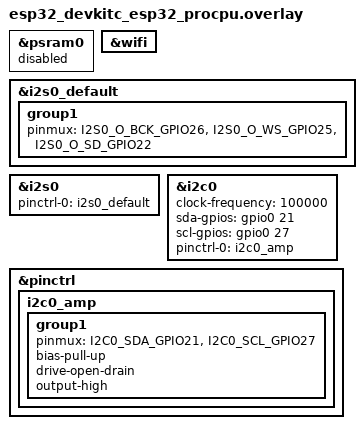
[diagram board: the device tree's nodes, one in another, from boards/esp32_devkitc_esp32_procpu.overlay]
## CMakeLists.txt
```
cmake_minimum_required(VERSION 3.20.0)
list(APPEND ZEPHYR_EXTRA_MODULES ${CMAKE_CURRENT_LIST_DIR}/../..)
find_package(Zephyr REQUIRED HINTS $ENV{ZEPHYR_BASE})
project(eaf_esp32_sendspin)
# Keep the optional silent backend within the WROOM budget; match all TUs.
zephyr_compile_definitions(EAF_NULL_MAX_FRAMES=128u)
set(EAF_PRIVATE_CONFIG "${CMAKE_CURRENT_SOURCE_DIR}/credentials.local.h" CACHE FILEPATH "Local Wi-Fi credentials header")
if(EXISTS "${EAF_PRIVATE_CONFIG}")
  configure_file("${EAF_PRIVATE_CONFIG}" private/credentials.h COPYONLY)
else()
  configure_file(credentials.example.h private/credentials.h COPYONLY)
  message(STATUS "No local Wi-Fi credentials: image builds but will not connect")
endif()
target_include_directories(app PRIVATE ${CMAKE_CURRENT_BINARY_DIR}/private)
target_sources(app PRIVATE src/main.c)
target_sources(app PRIVATE ${CMAKE_CURRENT_SOURCE_DIR}/../esp32_output/board_output.c)
target_sources(app PRIVATE ${CMAKE_CURRENT_SOURCE_DIR}/../esp32_common/log_buffer.c
  ${CMAKE_CURRENT_SOURCE_DIR}/../esp32_common/diagnostics.c
  ${CMAKE_CURRENT_SOURCE_DIR}/../esp32_common/tas5805m.c
  ${CMAKE_CURRENT_SOURCE_DIR}/../esp32_common/tas5805m_zephyr.c
  ${CMAKE_CURRENT_SOURCE_DIR}/../esp32_common/wifi_bootstrap.c
  ${CMAKE_CURRENT_SOURCE_DIR}/../esp32_common/board_runtime.c)
target_include_directories(app PRIVATE ${CMAKE_CURRENT_SOURCE_DIR}/../esp32_output
  ${CMAKE_CURRENT_SOURCE_DIR}/../esp32_common
  ${CMAKE_CURRENT_SOURCE_DIR}/../../hal/zephyr)
if(CONFIG_EAF_BOARD_I2S)
  target_sources(app PRIVATE ${CMAKE_CURRENT_SOURCE_DIR}/../esp32_output/sink_i2s.c)
else()
  target_sources(app PRIVATE ${CMAKE_CURRENT_SOURCE_DIR}/../esp32_output/sink_null.c)
endif()
if(CONFIG_EAF_BOARD_USE_PSRAM)
  target_sources(app PRIVATE ${CMAKE_CURRENT_SOURCE_DIR}/../esp32_output/storage_psram.c)
else()
  target_sources(app PRIVATE ${CMAKE_CURRENT_SOURCE_DIR}/../esp32_output/storage_internal.c)
endif()
if(CONFIG_WIFI_ESP32)
  target_sources(app PRIVATE ${CMAKE_CURRENT_SOURCE_DIR}/../esp32_common/wifi_power_esp32.c)
else()
  target_sources(app PRIVATE ${CMAKE_CURRENT_SOURCE_DIR}/../esp32_common/wifi_power_stub.c)
endif()
if(CONFIG_BOOTLOADER_MCUBOOT)
  target_sources(app PRIVATE ${CMAKE_CURRENT_SOURCE_DIR}/../esp32_common/ota_mcuboot.c)
else()
  target_sources(app PRIVATE ${CMAKE_CURRENT_SOURCE_DIR}/../esp32_common/ota_stub.c)
endif()

target_include_directories(app SYSTEM PRIVATE ${ZEPHYR_BASE}/include)
target_compile_options(app PRIVATE -Wall -Wextra -Werror -Wconversion -Wstrict-prototypes -Wshadow -Wdouble-promotion)
```

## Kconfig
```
mainmenu "EAF WROOM Sendspin player"
config EAF_I2S_MAX_FRAMES
    default 128
source "Kconfig.zephyr"
config EAF_BOARD_I2S
    bool "Audible I2S output (otherwise timed null)"
    default y
    select I2S
    select EAF_I2S
config EAF_BOARD_NAME
    string "Player name advertised to the server"
    default "EAF Sendspin"
    help
      Human-readable name shown in Music Assistant. Set a distinct value per
      board so multiple players are easy to tell apart.

config EAF_BOARD_CLIENT_ID
    string "Sendspin client identifier"
    default "eaf-sendspin"
    help
      Stable identifier for this player. Changing it makes the server treat
      the board as a new player.

config EAF_BOARD_SERVER
    string "Sendspin server numeric IPv4 address"
    default ""
    help
      Music Assistant host IPv4 address. Required; the board logs an error and
      stops when it is empty. Provide it locally, for example with a local
      override file passed as -DEXTRA_CONF_FILE=local.conf containing
      CONFIG_EAF_BOARD_SERVER="192.168.1.10".
config EAF_BOARD_PORT
    int "Sendspin server port"
    default 8927
    range 1 65535
config EAF_SOURCE_CHANNELS
    int "Source PCM channels advertised to the server"
    default 2
    range 1 2
    help
      Ask Music Assistant to send this many channels. The board still outputs
      stereo (the producer duplicates one channel when mono), but the network
      rate drops when set to 1, which is more reliable on throughput-limited
      2.4 GHz Wi-Fi.

choice EAF_BIT_DEPTH_CHOICE
    prompt "Source PCM bit depth advertised to the server"
    default EAF_BIT_DEPTH_16
    help
      Precision of the PCM the server sends. The board always presents 32-bit
      Q1.31 to the I2S sink; the network rate grows with the chosen precision.

config EAF_BIT_DEPTH_16
    bool "16-bit"
config EAF_BIT_DEPTH_24
    bool "24-bit"
config EAF_BIT_DEPTH_32
    bool "32-bit"
endchoice

config EAF_BIT_DEPTH
    int
    default 16 if EAF_BIT_DEPTH_16
    default 24 if EAF_BIT_DEPTH_24
    default 32 if EAF_BIT_DEPTH_32

config EAF_SAMPLE_RATE
    int "Source sample rate advertised to the server"
    default 44100
    range 8000 192000
    help
      Music Assistant transcodes to this rate. Lowering it (for example 22050)
      further reduces the network rate when even mono 44.1 kHz is marginal.

config EAF_AMP_PWDN_GPIO
    int "TAS5805M PDN GPIO (amplifier enable)"
    default 33
    range 0 39
config EAF_AMP_FAULT_GPIO
    int "TAS5805M FAULT GPIO (input)"
    default 34
    range 0 39
config EAF_BOARD_RATE_CONTROL
    bool "Hold presentation latency with drift resampling"
    default y
    help
      Resample the PCM written to the sink to hold the measured Sendspin
      presentation latency at the reported lead time. Required for synchronized
      multiroom playback; the correction is bounded to a few hundred ppm.

config EAF_BOARD_WIFI_PS_NONE
    bool "Disable Wi-Fi modem sleep for lower latency"
    default y
    help
      ESP-IDF defaults to WIFI_PS_MIN_MODEM, which wakes only at the AP DTIM
      period. On a mains-powered player, disabling power save removes those
      periodic receive stalls at the cost of higher idle current.
config EAF_BOARD_AUDIO_CPU
    int "Audio worker CPU (-1 unrestricted)"
    default -1
    help
      With CONFIG_SMP and CONFIG_SCHED_CPU_MASK, pin the audio owner to this
      CPU so network work cannot preempt it. -1 leaves it unrestricted.
config EAF_BOARD_MAIN_CPU
    int "Main/transport CPU (-1 unrestricted)"
    default -1
config EAF_BOARD_RESERVOIR_FRAMES
    int "Output reservoir capacity in frames (power of two)"
    default 4096
    range 512 1048576
    help
      Stereo Q1.31 output reservoir capacity. Also caps the startup prefill.
      Must be a power of two.
config EAF_BOARD_USE_PSRAM
    bool "Place the output reservoir in external SPI RAM"
    default n
    depends on ESP_SPIRAM
    help
      Allocate the reservoir from the ESP32 external RAM shared heap. Enables
      the large-buffer WROVER profile; requires CONFIG_ESP_SPIRAM and PSRAM.
```

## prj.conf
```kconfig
CONFIG_EAF=y
CONFIG_EAF_SENDPIN=y
CONFIG_EAF_LMS=n
CONFIG_EAF_LMS_CLIENT=n
CONFIG_EAF_BT_INGRESS=n
CONFIG_EAF_BT_SBC=n
CONFIG_EAF_BT_A2DP=n
CONFIG_EAF_THREAD_COUNT=1
CONFIG_EAF_THREAD_STACK_SIZE=4096
CONFIG_MAIN_STACK_SIZE=6144
CONFIG_MAIN_THREAD_PRIORITY=5
CONFIG_EAF_SEM_COUNT=1
CONFIG_ASSERT=y
CONFIG_REBOOT=y
CONFIG_THREAD_STACK_INFO=y
CONFIG_INIT_STACKS=y
CONFIG_REQUIRES_FULL_LIBC=y
CONFIG_WIFI=y
CONFIG_NET_L2_WIFI_MGMT=y
CONFIG_NETWORKING=y
CONFIG_I2C=y
CONFIG_NET_IPV4=y
CONFIG_NET_IPV6=n
CONFIG_NET_TCP=y
CONFIG_NET_DHCPV4=y
CONFIG_NET_SOCKETS=y
CONFIG_NET_MGMT=y
CONFIG_NET_MGMT_EVENT=y
CONFIG_NET_MGMT_EVENT_INFO=y
CONFIG_NET_MAX_CONTEXTS=10
CONFIG_NET_MAX_CONN=12
CONFIG_NET_PKT_RX_COUNT=12
CONFIG_NET_PKT_TX_COUNT=8
CONFIG_NET_BUF_RX_COUNT=64
CONFIG_NET_BUF_TX_COUNT=16
CONFIG_NET_BUF_DATA_SIZE=256
CONFIG_NET_TCP_MAX_RECV_WINDOW_SIZE=8192
CONFIG_NET_CONTEXT_RCVTIMEO=y
CONFIG_NET_CONTEXT_SNDTIMEO=y
CONFIG_HEAP_MEM_POOL_SIZE=65536
```

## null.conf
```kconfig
CONFIG_EAF_BOARD_I2S=n
```

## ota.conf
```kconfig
# MCUboot OTA profile (ESP32).
#
# Requires a one-time flash of the MCUboot bootloader and this application to
# slot0; afterwards the running app can write slot1 over HTTP and request an
# upgrade. Enable with:
#   -DEXTRA_CONF_FILE="psram.conf;ota.conf"
CONFIG_ESP_SIMPLE_BOOT=n
CONFIG_BOOTLOADER_MCUBOOT=y
CONFIG_IMG_MANAGER=y
CONFIG_MCUBOOT_IMG_MANAGER=y
CONFIG_FLASH=y
CONFIG_FLASH_MAP=y
CONFIG_FLASH_PAGE_LAYOUT=y
CONFIG_STREAM_FLASH=y
CONFIG_MPU_ALLOW_FLASH_WRITE=y
CONFIG_REBOOT=y
```

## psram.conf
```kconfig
# WROVER-IE / ESP32-WROVER-E (N16R8 or similar) profile.
#
# Enable the 8 MB SPI RAM and place the stereo Q1.31 output reservoir there.
# 65536 frames (~1.5 s of 44.1 kHz stereo source) gives the jitter buffer needed
# to ride out Wi-Fi throughput dips that starve the 4096-frame WROOM profile.
#
# Build with:
#   cmake ... -DEXTRA_CONF_FILE=psram.conf -DEXTRA_DTC_OVERLAY_FILE=psram.overlay

# ESP32-WROVER-E N16R8: 16 MB flash (overrides the WROOM board's 4 MB).
CONFIG_ESPTOOLPY_FLASHSIZE_16MB=y

CONFIG_ESP_SPIRAM=y
CONFIG_ESP_SPIRAM_MEMTEST=y
CONFIG_ESP_SPIRAM_HEAP_SIZE=2097152
# The 2 MB SPIRAM heap exceeds the small-heap limit (262136 B), which is the
# 32-bit default when SRAM_SIZE <= 256. Use the runtime-sized heap.
CONFIG_SYS_HEAP_AUTO=y

CONFIG_EAF_BOARD_USE_PSRAM=y
CONFIG_EAF_BOARD_RESERVOIR_FRAMES=65536

# The larger PSRAM jitter buffer targets stereo; override the WROOM mono default.
CONFIG_EAF_SOURCE_CHANNELS=2
```

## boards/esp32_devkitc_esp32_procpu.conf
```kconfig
# WROOM has no external RAM. The upstream DevKitC template names a WROVER.
CONFIG_ESP_SPIRAM=n
CONFIG_ESP_SIMPLE_BOOT=y
CONFIG_ESPTOOLPY_FLASHSIZE_4MB=y
CONFIG_ESPTOOLPY_FLASHMODE_DIO=y
CONFIG_ESPTOOLPY_FLASHFREQ_40M=y
CONFIG_ESP32_WIFI_STATIC_RX_BUFFER_NUM=10
CONFIG_ESP32_WIFI_DYNAMIC_RX_BUFFER_NUM=16
CONFIG_ESP32_WIFI_DYNAMIC_TX_BUFFER_NUM=8
# AMPDU block-ack window; default 6 is low for a crowded 2.4 GHz link.
CONFIG_ESP32_WIFI_RX_BA_WIN=10

# The application owns DHCP and retry timing.
CONFIG_ESP32_WIFI_STA_AUTO_DHCPV4=n
CONFIG_ESP32_WIFI_STA_RECONNECT=n

# Back the TCP receive window with enough RX buffers for real-time PCM intake.
CONFIG_NET_TCP_MAX_RECV_WINDOW_SIZE=16384
CONFIG_NET_BUF_RX_COUNT=96
CONFIG_NET_PKT_RX_COUNT=24

# WROOM Wi-Fi cannot reliably sustain 176 kB/s stereo PCM16. Ask MA for mono
# (~88 kB/s); the producer still expands it to stereo for the I2S sink. The
# WROVER/PSRAM profile overrides this back to stereo.
CONFIG_EAF_SOURCE_CHANNELS=1

# Zephyr 4.3's ESP32 Wi-Fi driver depends on !SMP, so dual-core pinning is not
# available with networking. Keep audio above network work on the single core:
# the TCP worker default (2) outranks EAF audio (3); move it below.
CONFIG_NET_TCP_WORKER_PRIO=5
```

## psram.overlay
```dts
&psram0 { status = "okay"; };
```

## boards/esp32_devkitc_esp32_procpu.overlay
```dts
#include <zephyr/dt-bindings/gpio/gpio.h>
#include <zephyr/dt-bindings/pinctrl/esp-pinctrl-common.h>
#include <zephyr/dt-bindings/pinctrl/esp32-gpio-sigmap.h>
#include <zephyr/dt-bindings/pinctrl/esp32-pinctrl.h>

&psram0 { status = "disabled"; };
&wifi { status = "okay"; };

/* Board 2 (WROVER + TAS5805M): I2S WS=25, BCLK=26, DIN=22. */
&i2s0_default {
    group1 {
        pinmux = <I2S0_O_BCK_GPIO26>, <I2S0_O_WS_GPIO25>, <I2S0_O_SD_GPIO22>;
    };
};
&i2s0 {
    status = "okay";
    pinctrl-0 = <&i2s0_default>;
    pinctrl-names = "default";
};

/* TAS5805M I2C: SDA=GPIO21, SCL=GPIO27. */
&i2c0 {
    status = "okay";
    clock-frequency = <100000>;
    sda-gpios = <&gpio0 21 GPIO_OPEN_DRAIN>;
    scl-gpios = <&gpio0 27 GPIO_OPEN_DRAIN>;
    pinctrl-0 = <&i2c0_amp>;
    pinctrl-names = "default";
};
&pinctrl {
    i2c0_amp: i2c0_amp {
        group1 {
            pinmux = <I2C0_SDA_GPIO21>, <I2C0_SCL_GPIO27>;
            bias-pull-up;
            drive-open-drain;
            output-high;
        };
    };
};
```

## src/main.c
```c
#include "board_runtime.h"
#include "diagnostics.h"
#include "ota.h"
#include "tas5805m.h"
#include "wifi_bootstrap.h"
#include <board_output.h>
#include <eaf/eaf_hal.h>
#include <eaf/eaf_sendspin_client.h>
#include <eaf/eaf_sendspin_player.h>
#include <string.h>
#include <zephyr/kernel.h>
#include <zephyr/net/net_if.h>
#include <zephyr/sys/reboot.h>

/* dhcpv4.h requires the net_if declaration first. */
#include <zephyr/net/dhcpv4.h>
#include <zephyr/net/net_mgmt.h>
#include <zephyr/net/wifi_mgmt.h>
#include <zephyr/sys/byteorder.h>

BUILD_ASSERT(!IS_ENABLED(CONFIG_BT), "Qualify Wi-Fi alone before enabling Bluetooth");

static eaf_sendspin_client_t client;
static eaf_sendspin_player_t player;
static const tas5805m_io_t *board_amp;
static board_wifi_t wifi;
static atomic_t chunks;

static void sendspin_output_log(const char *message) {
    board_log("%s", message);
}

static uint32_t board_write(void *ctx, const int32_t *samples, uint32_t frames) {
    (void)ctx;
    return eaf_board_output_write(samples, frames);
}
static void on_ready(void *ctx, const eaf_sendspin_server_hello_t *hello) {
    (void)ctx;
    board_log("Sendspin ready: %.*s player=%d\n", (int)hello->name_length, hello->name,
              (int)hello->player_active);
}
static eaf_sendspin_stream_start_t current_stream;
static bool have_stream;

static void apply_volume(void);

static void start_output(const eaf_sendspin_stream_start_t *start) {
    have_stream = false;
    eaf_sendspin_player_finish(&player);
    eaf_format_t format = {.sample_rate = start->sample_rate,
                           .num_channels = 2,
                           .channel_mask = EAF_CH_FRONT_LEFT | EAF_CH_FRONT_RIGHT};
    uint32_t capacity = eaf_board_output_capacity_frames();
    int rc = eaf_board_output_replace(&format, capacity * 3u / 4u, false);
    if (!rc)
        rc = eaf_sendspin_player_begin(&player, &client.filter, start);
    if (rc) {
        board_log("Stream start failed rc=%d\n", rc);
    } else {
        have_stream = true;
        apply_volume();
        if (board_amp)
            (void)tas5805m_play(board_amp);
        board_log("Stream: %u Hz %u-bit %u ch\n", start->sample_rate, start->bit_depth,
                  start->channels);
    }
}
static void on_stream_start(void *ctx, const eaf_sendspin_stream_start_t *start) {
    (void)ctx;
    current_stream = *start;
    start_output(start);
}
static void on_audio(void *ctx, const eaf_sendspin_stream_start_t *format, int64_t timestamp_us,
                     const uint8_t *pcm, size_t length) {
    (void)ctx;
    (void)format;
    uint32_t before = player.frames_written;
    (void)eaf_sendspin_player_write(&player, timestamp_us, pcm, length);
    if (player.frames_written != before)
        atomic_inc(&chunks);
}
static void on_stream_end(void *ctx, bool end_player) {
    (void)ctx;
    if (end_player) {
        have_stream = false;
        eaf_sendspin_player_finish(&player);
        eaf_board_output_finish();
    }
}
static void on_stream_clear(void *ctx, bool clear_player) {
    (void)ctx;
    if (clear_player && have_stream) {
        board_log("Stream clear; flushing buffered audio\n");
        start_output(&current_stream);
    }
}
static int32_t volume_level = 100;
static bool volume_muted;

/* Perceptual square-law mapping from the server's 0..100 to Q1.31 gain. */
static int32_t volume_to_gain(int32_t percent) {
    if (percent <= 0)
        return 0;
    if (percent >= 100)
        return INT32_MAX;
    int64_t value = percent;
    return (int32_t)(value * value * INT32_MAX / 10000);
}
static void apply_volume(void) {
    int32_t gain = volume_muted ? 0 : volume_to_gain(volume_level);
    (void)eaf_board_output_volume(gain, gain);
}
static void on_command(void *ctx, const eaf_sendspin_server_command_t *command) {
    (void)ctx;
    if (command->command == EAF_SENDPIN_COMMAND_VOLUME && command->volume >= 0) {
        volume_level = command->volume;
        board_log("Volume=%d\n", volume_level);
        apply_volume();
    } else if (command->command == EAF_SENDPIN_COMMAND_MUTE) {
        volume_muted = command->muted;
        board_log("Mute=%d\n", (int)volume_muted);
        apply_volume();
    }
}
static void on_disconnect(void *ctx) {
    (void)ctx;
    board_log("Sendspin disconnected\n");
}

int main(void) {
    board_diagnostics_start();
    if (board_wifi_bind(&wifi) != EAF_OK)
        return 1;
    struct in_addr server;
    if (!strlen(CONFIG_EAF_BOARD_SERVER) ||
        net_addr_pton(AF_INET, CONFIG_EAF_BOARD_SERVER, &server)) {
        board_log("Set CONFIG_EAF_BOARD_SERVER to the Music Assistant IPv4 address\n");
        return 1;
    }

    int32_t *storage;
    uint32_t frames;
    if (eaf_board_output_storage(&storage, &frames)) {
        board_log("Output storage allocation failed\n");
        return 1;
    }
    eaf_board_output_config_t output_config = {.audio_cpu = CONFIG_EAF_BOARD_AUDIO_CPU,
                                               .log = sendspin_output_log,
                                               .storage = storage,
                                               .capacity_frames = frames};
    if (eaf_board_output_init(&output_config)) {
        board_log("Output initialization failed\n");
        return 1;
    }
    board_amp = tas5805m_board_io();
    (void)tas5805m_bringup(board_amp);
    eaf_sendspin_player_init(&player, board_write, NULL);

    uint32_t capacity = eaf_board_output_capacity_frames();
    uint32_t capacity_ms = capacity * 1000u / CONFIG_EAF_SAMPLE_RATE;
    if (IS_ENABLED(CONFIG_EAF_BOARD_RATE_CONTROL))
        eaf_sendspin_player_set_rate_control(&player, 0.0); /* auto target */
    eaf_sendspin_config_t config = {.client_id = CONFIG_EAF_BOARD_CLIENT_ID,
                                    .name = CONFIG_EAF_BOARD_NAME,
                                    .product_name = CONFIG_EAF_BOARD_NAME,
                                    .manufacturer = "EAF",
                                    .software_version = "phase2",
                                    .sample_rate = CONFIG_EAF_SAMPLE_RATE,
                                    .bit_depth = CONFIG_EAF_BIT_DEPTH,
                                    .support_volume = true,
                                    .support_mute = true,
                                    .volume = 100,
                                    .static_delay_ms = 0,
                                    .required_lead_time_ms = (int32_t)capacity_ms,
                                    .min_buffer_ms = (int32_t)capacity_ms};
    config.channels = CONFIG_EAF_SOURCE_CHANNELS;
    config.buffer_capacity =
        capacity * CONFIG_EAF_SOURCE_CHANNELS * (uint32_t)(CONFIG_EAF_BIT_DEPTH / 8);
    eaf_sendspin_callbacks_t callbacks = {.ready = on_ready,
                                          .stream_start = on_stream_start,
                                          .audio = on_audio,
                                          .stream_end = on_stream_end,
                                          .stream_clear = on_stream_clear,
                                          .command = on_command,
                                          .disconnected = on_disconnect};
    eaf_sendspin_client_init(&client, &config, &callbacks, NULL);

    board_log("EAF Sendspin board: server %s:%d\n", CONFIG_EAF_BOARD_SERVER, CONFIG_EAF_BOARD_PORT);
    for (;;) {
        int rc = board_wifi_online(&wifi) ? EAF_OK : board_wifi_connect(&wifi);
        if (!rc)
            rc = eaf_sendspin_client_connect(&client, sys_be32_to_cpu(server.s_addr),
                                             (uint16_t)CONFIG_EAF_BOARD_PORT, 3000);
        if (rc) {
            board_log("Sendspin connect failed rc=%d\n", rc);
            k_sleep(K_SECONDS(3));
            continue;
        }
        board_log("Sendspin connected; select this player in Music Assistant\n");
        int64_t report = 0;
        uint64_t previous_rx = client.rx_total;
        int64_t previous_ms = k_uptime_get();
        while (!rc && board_wifi_online(&wifi) && !eaf_board_output_failed()) {
            /* Drain the socket greedily so the server's TCP window stays open. */
            uint64_t before = client.rx_total;
            for (unsigned i = 0; i < 8 && !rc; ++i) {
                rc = eaf_sendspin_client_step(&client);
                if (client.rx_total == before)
                    break;
                before = client.rx_total;
            }
            int64_t now = k_uptime_get();
            if (now >= report) {
                uint64_t span = (uint64_t)(now - previous_ms);
                uint64_t rate = span ? (client.rx_total - previous_rx) * 1000u / span : 0;
                board_log("Sendspin chunks=%u written=%u dropped=%u underruns=%u sync=%d "
                          "lat_ms=%lld level=%u flags=%u rx=%llu B/s vol=%d mute=%d ppm=%d "
                          "fault=%d\n",
                          (unsigned)atomic_get(&chunks), player.frames_written,
                          player.frames_dropped, eaf_board_output_underruns(),
                          (int)player.synchronized, (long long)(player.last_latency_us / 1000),
                          eaf_board_output_level(), eaf_board_output_flags(),
                          (unsigned long long)rate, volume_level, (int)volume_muted,
                          (int)player.rate_ppm, board_amp ? (int)tas5805m_fault(board_amp) : 0);
                board_wifi_health(&wifi);
                previous_rx = client.rx_total;
                previous_ms = now;
                report = now + 5000;
            }
            if (ota_reboot_requested()) {
                board_log("OTA reboot\n");
                k_sleep(K_MSEC(200));
                sys_reboot(SYS_REBOOT_COLD);
            }
            k_sleep(K_MSEC(1));
        }
        eaf_sendspin_client_close(&client);
        eaf_sendspin_player_finish(&player);
        eaf_board_output_stop();
        if (eaf_board_output_failed()) {
            board_log("Output failure: playback stopped\n");
            return 1;
        }
        if (!board_wifi_online(&wifi)) {
            (void)net_mgmt(NET_REQUEST_WIFI_DISCONNECT, wifi.iface, NULL, 0);
            net_dhcpv4_stop(wifi.iface);
        }
        k_sleep(K_SECONDS(3));
    }
    return 0;
}
```

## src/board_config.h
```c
#pragma once
const char *board_wifi_ssid(void);
const char *board_wifi_password(void);
```

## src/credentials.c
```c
#include "credentials.h"
#include "board_config.h"

/* Private strings are never printed or passed to Kconfig. */
const char *board_wifi_ssid(void) {
    return EAF_WIFI_SSID;
}
const char *board_wifi_password(void) {
    return EAF_WIFI_PASSWORD;
}
```
